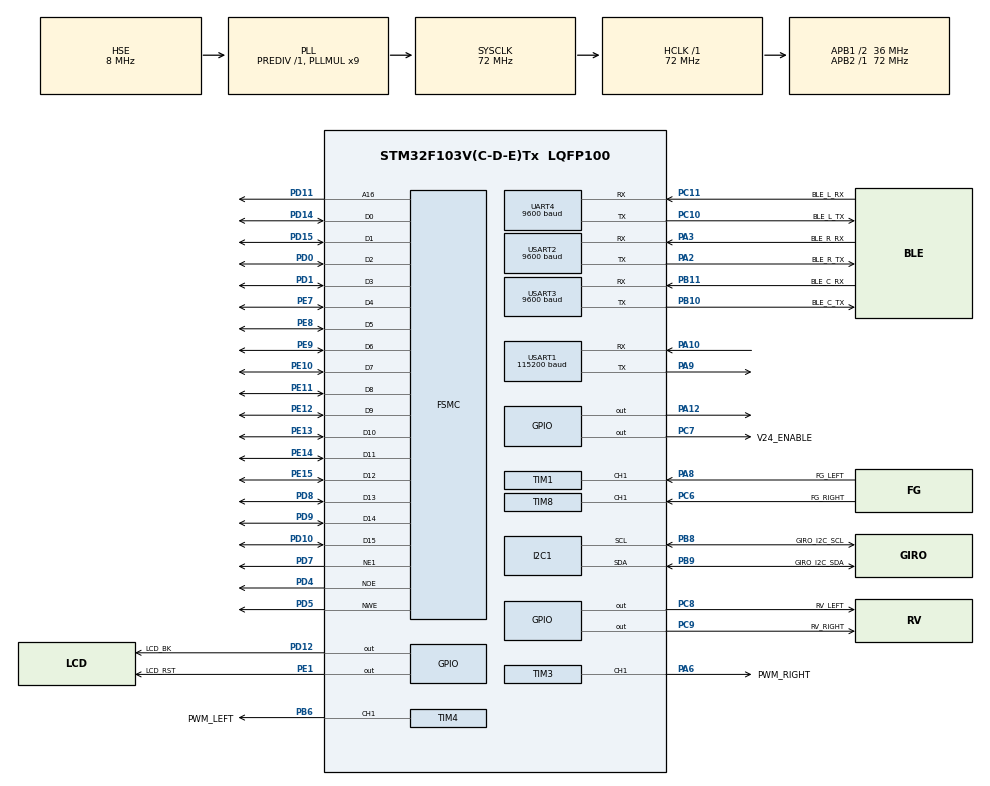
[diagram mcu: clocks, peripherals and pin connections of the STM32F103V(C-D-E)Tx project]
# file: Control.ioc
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Dma.Request0=UART4_RX
Dma.Request1=UART4_TX
Dma.Request2=USART2_RX
Dma.Request3=USART2_TX
Dma.Request4=USART1_RX
Dma.Request5=USART1_TX
Dma.Request6=USART3_RX
Dma.Request7=USART3_TX
Dma.UART4_RX.0.Direction=DMA_PERIPH_TO_MEMORY
Dma.UART4_RX.0.Instance=DMA2_Channel3
Dma.UART4_RX.0.MemDataAlignment=DMA_MDATAALIGN_BYTE
Dma.UART4_RX.0.MemInc=DMA_MINC_ENABLE
Dma.UART4_RX.0.Mode=DMA_CIRCULAR
Dma.UART4_RX.0.PeriphDataAlignment=DMA_PDATAALIGN_BYTE
Dma.UART4_RX.0.PeriphInc=DMA_PINC_DISABLE
Dma.UART4_RX.0.Priority=DMA_PRIORITY_HIGH
Dma.UART4_TX.1.Direction=DMA_MEMORY_TO_PERIPH
Dma.UART4_TX.1.Instance=DMA2_Channel5
Dma.UART4_TX.1.MemDataAlignment=DMA_MDATAALIGN_BYTE
Dma.UART4_TX.1.MemInc=DMA_MINC_ENABLE
Dma.UART4_TX.1.Mode=DMA_NORMAL
Dma.UART4_TX.1.PeriphDataAlignment=DMA_PDATAALIGN_BYTE
Dma.UART4_TX.1.PeriphInc=DMA_PINC_DISABLE
Dma.UART4_TX.1.Priority=DMA_PRIORITY_LOW
Dma.USART1_RX.4.Direction=DMA_PERIPH_TO_MEMORY
Dma.USART1_RX.4.Instance=DMA1_Channel5
Dma.USART1_RX.4.MemDataAlignment=DMA_MDATAALIGN_BYTE
Dma.USART1_RX.4.MemInc=DMA_MINC_ENABLE
Dma.USART1_RX.4.Mode=DMA_CIRCULAR
Dma.USART1_RX.4.PeriphDataAlignment=DMA_PDATAALIGN_BYTE
Dma.USART1_RX.4.PeriphInc=DMA_PINC_DISABLE
Dma.USART1_RX.4.Priority=DMA_PRIORITY_HIGH
Dma.USART1_TX.5.Direction=DMA_MEMORY_TO_PERIPH
Dma.USART1_TX.5.Instance=DMA1_Channel4
Dma.USART1_TX.5.MemDataAlignment=DMA_MDATAALIGN_BYTE
Dma.USART1_TX.5.MemInc=DMA_MINC_ENABLE
Dma.USART1_TX.5.Mode=DMA_NORMAL
Dma.USART1_TX.5.PeriphDataAlignment=DMA_PDATAALIGN_BYTE
Dma.USART1_TX.5.PeriphInc=DMA_PINC_DISABLE
Dma.USART1_TX.5.Priority=DMA_PRIORITY_LOW
Dma.USART2_RX.2.Direction=DMA_PERIPH_TO_MEMORY
Dma.USART2_RX.2.Instance=DMA1_Channel6
Dma.USART2_RX.2.MemDataAlignment=DMA_MDATAALIGN_BYTE
Dma.USART2_RX.2.MemInc=DMA_MINC_ENABLE
Dma.USART2_RX.2.Mode=DMA_CIRCULAR
Dma.USART2_RX.2.PeriphDataAlignment=DMA_PDATAALIGN_BYTE
Dma.USART2_RX.2.PeriphInc=DMA_PINC_DISABLE
Dma.USART2_RX.2.Priority=DMA_PRIORITY_HIGH
Dma.USART2_TX.3.Direction=DMA_MEMORY_TO_PERIPH
Dma.USART2_TX.3.Instance=DMA1_Channel7
Dma.USART2_TX.3.MemDataAlignment=DMA_MDATAALIGN_BYTE
Dma.USART2_TX.3.MemInc=DMA_MINC_ENABLE
Dma.USART2_TX.3.Mode=DMA_NORMAL
Dma.USART2_TX.3.PeriphDataAlignment=DMA_PDATAALIGN_BYTE
Dma.USART2_TX.3.PeriphInc=DMA_PINC_DISABLE
Dma.USART2_TX.3.Priority=DMA_PRIORITY_LOW
Dma.USART3_RX.6.Direction=DMA_PERIPH_TO_MEMORY
Dma.USART3_RX.6.Instance=DMA1_Channel3
Dma.USART3_RX.6.MemDataAlignment=DMA_MDATAALIGN_BYTE
Dma.USART3_RX.6.MemInc=DMA_MINC_ENABLE
Dma.USART3_RX.6.Mode=DMA_CIRCULAR
Dma.USART3_RX.6.PeriphDataAlignment=DMA_PDATAALIGN_BYTE
Dma.USART3_RX.6.PeriphInc=DMA_PINC_DISABLE
Dma.USART3_RX.6.Priority=DMA_PRIORITY_HIGH
Dma.USART3_TX.7.Direction=DMA_MEMORY_TO_PERIPH
Dma.USART3_TX.7.Instance=DMA1_Channel2
Dma.USART3_TX.7.MemDataAlignment=DMA_MDATAALIGN_BYTE
Dma.USART3_TX.7.MemInc=DMA_MINC_ENABLE
Dma.USART3_TX.7.Mode=DMA_NORMAL
Dma.USART3_TX.7.PeriphDataAlignment=DMA_PDATAALIGN_BYTE
Dma.USART3_TX.7.PeriphInc=DMA_PINC_DISABLE
Dma.USART3_TX.7.Priority=DMA_PRIORITY_LOW
FREERTOS.INCLUDE_uxTaskGetStackHighWaterMark=0
FREERTOS.Tasks01=RT_Main,24,512,rtmain,As weak,NULL,Static,RT_MainBuffer,RT_MainControlBlock
FREERTOS.configCHECK_FOR_STACK_OVERFLOW=0
FREERTOS.configENABLE_BACKWARD_COMPATIBILITY=0
FREERTOS.configTOTAL_HEAP_SIZE=32768
FREERTOS.configUSE_IDLE_HOOK=1
FREERTOS.configUSE_PREEMPTION=0
FREERTOS.configUSE_TRACE_FACILITY=0
Mcu.Family=STM32F1
Mcu.Name=STM32F103V(C-D-E)Tx
Mcu.Package=LQFP100
NVIC.DMA1_Channel2_IRQn=true\:5\:0\:false\:false\:true\:true\:false\:true
NVIC.DMA1_Channel3_IRQn=true\:5\:0\:false\:false\:true\:true\:false\:true
NVIC.DMA1_Channel4_IRQn=true\:5\:0\:false\:false\:true\:true\:false\:true
NVIC.DMA1_Channel5_IRQn=true\:5\:0\:false\:false\:true\:true\:false\:true
NVIC.DMA1_Channel6_IRQn=true\:5\:0\:false\:false\:true\:true\:false\:true
NVIC.DMA1_Channel7_IRQn=true\:5\:0\:false\:false\:true\:true\:false\:true
NVIC.DMA2_Channel3_IRQn=true\:5\:0\:false\:false\:true\:true\:false\:true
NVIC.DMA2_Channel4_5_IRQn=true\:5\:0\:false\:false\:true\:true\:false\:true
NVIC.PriorityGroup=NVIC_PRIORITYGROUP_4
NVIC.TIM1_CC_IRQn=true\:5\:0\:false\:false\:true\:false\:true\:true
NVIC.TIM7_IRQn=true\:0\:0\:false\:false\:true\:false\:false\:true
NVIC.TIM8_CC_IRQn=true\:5\:0\:false\:false\:true\:false\:true\:true
NVIC.TimeBase=TIM7_IRQn
NVIC.TimeBaseIP=TIM7
NVIC.UART4_IRQn=true\:5\:0\:false\:false\:true\:false\:true\:true
NVIC.USART1_IRQn=true\:5\:0\:false\:false\:true\:true\:true\:true
NVIC.USART2_IRQn=true\:5\:0\:false\:false\:true\:false\:true\:true
NVIC.USART3_IRQn=true\:5\:0\:false\:false\:true\:true\:true\:true
OSC_IN.Mode=HSE-External-Oscillator
OSC_IN.Signal=RCC_OSC_IN
OSC_OUT.Mode=HSE-External-Oscillator
OSC_OUT.Signal=RCC_OSC_OUT
PA10.Mode=Asynchronous
PA10.Signal=USART1_RX
PA12.PinState=GPIO_PIN_RESET
PA12.Signal=GPIO_Output
PA13.Mode=JTAG_4_pins
PA13.Signal=SYS_JTMS-SWDIO
PA14.Mode=JTAG_4_pins
PA14.Signal=SYS_JTCK-SWCLK
PA15.Mode=JTAG_4_pins
PA15.Signal=SYS_JTDI
PA2.GPIO_Label=BLE_R_TX
PA2.Mode=Asynchronous
PA2.Signal=USART2_TX
PA3.GPIO_Label=BLE_R_RX
PA3.Mode=Asynchronous
PA3.Signal=USART2_RX
PA6.GPIO_Label=PWM_RIGHT
PA6.GPIO_ModeDefaultPP=GPIO_MODE_AF_PP
PA6.GPIO_Speed=GPIO_SPEED_FREQ_HIGH
PA6.Signal=S_TIM3_CH1
PA8.GPIO_Label=FG_LEFT
PA8.GPIO_Mode=GPIO_MODE_INPUT
PA8.GPIO_PuPd=GPIO_NOPULL
PA8.Signal=S_TIM1_CH1
PA9.Mode=Asynchronous
PA9.Signal=USART1_TX
PB10.GPIO_Label=BLE_C_TX
PB10.Mode=Asynchronous
PB10.Signal=USART3_TX
PB11.GPIO_Label=BLE_C_RX
PB11.Mode=Asynchronous
PB11.Signal=USART3_RX
PB3.Mode=JTAG_4_pins
PB3.Signal=SYS_JTDO-TRACESWO
PB6.GPIO_Label=PWM_LEFT
PB6.GPIO_Speed=GPIO_SPEED_FREQ_HIGH
PB6.Signal=S_TIM4_CH1
PB8.GPIO_Label=GIRO_I2C_SCL
PB8.Mode=I2C
PB8.Signal=I2C1_SCL
PB9.GPIO_Label=GIRO_I2C_SDA
PB9.Mode=I2C
PB9.Signal=I2C1_SDA
PC10.GPIO_Label=BLE_L_TX
PC10.Mode=Asynchronous
PC10.Signal=UART4_TX
PC11.GPIO_Label=BLE_L_RX
PC11.Mode=Asynchronous
PC11.Signal=UART4_RX
PC14-OSC32_IN.Mode=LSE-External-Oscillator
PC14-OSC32_IN.Signal=RCC_OSC32_IN
PC15-OSC32_OUT.Mode=LSE-External-Oscillator
PC15-OSC32_OUT.Signal=RCC_OSC32_OUT
PC6.GPIO_Label=FG_RIGHT
PC6.GPIO_Mode=GPIO_MODE_INPUT
PC6.GPIO_PuPd=GPIO_NOPULL
PC6.Signal=S_TIM8_CH1
PC7.GPIO_Label=V24_ENABLE
PC7.Signal=GPIO_Output
PC8.GPIO_Label=RV_LEFT
PC8.Signal=GPIO_Output
PC9.GPIO_Label=RV_RIGHT
PC9.Signal=GPIO_Output
PD0.Mode=16b-d1
PD0.Signal=FSMC_D2
PD1.Mode=16b-d1
PD1.Signal=FSMC_D3
PD10.Mode=16b-d1
PD10.Signal=FSMC_D15
PD11.Mode=A16_1
PD11.Signal=FSMC_A16
PD12.GPIO_Label=LCD_BK
PD12.Signal=GPIO_Output
PD14.Mode=16b-d1
PD14.Signal=FSMC_D0
PD15.Mode=16b-d1
PD15.Signal=FSMC_D1
PD4.Mode=Lcd1
PD4.Signal=FSMC_NOE
PD5.Mode=Lcd1
PD5.Signal=FSMC_NWE
PD7.Mode=NorPsramChipSelect1_1
PD7.Signal=FSMC_NE1
PD8.Mode=16b-d1
PD8.Signal=FSMC_D13
PD9.Mode=16b-d1
PD9.Signal=FSMC_D14
PE1.GPIO_Label=LCD_RST
PE1.Signal=GPIO_Output
PE10.Mode=16b-d1
PE10.Signal=FSMC_D7
PE11.Mode=16b-d1
PE11.Signal=FSMC_D8
PE12.Mode=16b-d1
PE12.Signal=FSMC_D9
PE13.Mode=16b-d1
PE13.Signal=FSMC_D10
PE14.Mode=16b-d1
PE14.Signal=FSMC_D11
PE15.Mode=16b-d1
PE15.Signal=FSMC_D12
PE7.Mode=16b-d1
PE7.Signal=FSMC_D4
PE8.Mode=16b-d1
PE8.Signal=FSMC_D5
PE9.Mode=16b-d1
PE9.Signal=FSMC_D6
ProjectManager.HeapSize=0x200
ProjectManager.StackSize=0x400
ProjectManager.TargetToolchain=STM32CubeIDE
RCC.AHBFreq_Value=72000000
RCC.APB1CLKDivider=RCC_HCLK_DIV2
RCC.APB1Freq_Value=36000000
RCC.APB1TimFreq_Value=72000000
RCC.APB2Freq_Value=72000000
RCC.APB2TimFreq_Value=72000000
RCC.HCLKFreq_Value=72000000
RCC.PLLMUL=RCC_PLL_MUL9
RCC.PLLSourceVirtual=RCC_PLLSOURCE_HSE
RCC.SYSCLKFreq_VALUE=72000000
RCC.SYSCLKSource=RCC_SYSCLKSOURCE_PLLCLK
RCC.USBFreq_Value=72000000
SH.S_TIM1_CH1.0=TIM1_CH1,Input_Capture1_from_TI1
SH.S_TIM3_CH1.0=TIM3_CH1,PWM Generation1 CH1
SH.S_TIM4_CH1.0=TIM4_CH1,PWM Generation1 CH1
SH.S_TIM8_CH1.0=TIM8_CH1,Input_Capture1_from_TI1
TIM1.Channel-Input_Capture1_from_TI1=TIM_CHANNEL_1
TIM1.Prescaler=1023
TIM3.Channel-PWM\ Generation1\ CH1=TIM_CHANNEL_1
TIM3.Period=6999
TIM3.Pulse-PWM\ Generation1\ CH1=2099
TIM4.Channel-PWM\ Generation1\ CH1=TIM_CHANNEL_1
TIM4.Period=6999
TIM4.Pulse-PWM\ Generation1\ CH1=2099
TIM8.Channel-Input_Capture1_from_TI1=TIM_CHANNEL_1
TIM8.Prescaler=1023
UART4.BaudRate=9600
UART4.VirtualMode=Asynchronous
USART1.BaudRate=115200
USART1.VirtualMode=VM_ASYNC
USART2.BaudRate=9600
USART2.VirtualMode=VM_ASYNC
USART3.BaudRate=9600
USART3.VirtualMode=VM_ASYNC
VP_FREERTOS_VS_CMSIS_V2.Mode=CMSIS_V2
VP_SYS_VS_tim7.Mode=TIM7
VP_TIM1_VS_ClockSourceINT.Mode=Internal
VP_TIM3_VS_ClockSourceINT.Mode=Internal
VP_TIM4_VS_ClockSourceINT.Mode=Internal
VP_TIM8_VS_ClockSourceINT.Mode=Internal
board=custom

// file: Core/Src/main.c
/* USER CODE BEGIN Header */
/**
  ******************************************************************************
  * @file           : main.c
  * @brief          : Main program body
  ******************************************************************************
  * @attention
  *
  * <h2><center>&copy; Copyright (c) 2020 STMicroelectronics.
  * All rights reserved.</center></h2>
  *
  * This software component is licensed by ST under BSD 3-Clause license,
  * the "License"; You may not use this file except in compliance with the
  * License. You may obtain a copy of the License at:
  *                        opensource.org/licenses/BSD-3-Clause
  *
  ******************************************************************************
  */
/* USER CODE END Header */
#include "main.h"
#include "cmsis_os.h"

typedef StaticTask_t osStaticThreadDef_t;

I2C_HandleTypeDef hi2c1;

TIM_HandleTypeDef htim1;
TIM_HandleTypeDef htim3;
TIM_HandleTypeDef htim4;
TIM_HandleTypeDef htim8;

UART_HandleTypeDef huart4;
UART_HandleTypeDef huart1;
UART_HandleTypeDef huart2;
UART_HandleTypeDef huart3;
DMA_HandleTypeDef hdma_uart4_rx;
DMA_HandleTypeDef hdma_uart4_tx;
DMA_HandleTypeDef hdma_usart1_rx;
DMA_HandleTypeDef hdma_usart1_tx;
DMA_HandleTypeDef hdma_usart2_rx;
DMA_HandleTypeDef hdma_usart2_tx;
DMA_HandleTypeDef hdma_usart3_rx;
DMA_HandleTypeDef hdma_usart3_tx;

SRAM_HandleTypeDef hsram1;

/* Definitions for RT_Main */
osThreadId_t RT_MainHandle;
uint32_t RT_MainBuffer[ 512 ];
osStaticThreadDef_t RT_MainControlBlock;
const osThreadAttr_t RT_Main_attributes = {
  .name = "RT_Main",
  .stack_mem = &RT_MainBuffer[0],
  .stack_size = sizeof(RT_MainBuffer),
  .cb_mem = &RT_MainControlBlock,
  .cb_size = sizeof(RT_MainControlBlock),
  .priority = (osPriority_t) osPriorityNormal,
};

void SystemClock_Config(void);
static void MX_GPIO_Init(void);
static void MX_DMA_Init(void);
static void MX_FSMC_Init(void);
static void MX_TIM1_Init(void);
static void MX_TIM3_Init(void);
static void MX_TIM8_Init(void);
static void MX_TIM4_Init(void);
static void MX_UART4_Init(void);
static void MX_USART2_UART_Init(void);
static void MX_USART1_UART_Init(void);
static void MX_USART3_UART_Init(void);
static void MX_I2C1_Init(void);
void rtmain(void *argument);

int main(void)
{

  /* MCU Configuration--------------------------------------------------------*/

  /* Reset of all peripherals, Initializes the Flash interface and the Systick. */
  HAL_Init();

  /* Configure the system clock */
  SystemClock_Config();

  /* Initialize all configured peripherals */
  MX_GPIO_Init();
  MX_DMA_Init();
  MX_FSMC_Init();
  MX_TIM1_Init();
  MX_TIM3_Init();
  MX_TIM8_Init();
  MX_TIM4_Init();
  MX_UART4_Init();
  MX_USART2_UART_Init();
  MX_USART1_UART_Init();
  MX_USART3_UART_Init();
  MX_I2C1_Init();

  /* Init scheduler */
  osKernelInitialize();

  /* Create the thread(s) */
  /* creation of RT_Main */
  RT_MainHandle = osThreadNew(rtmain, NULL, &RT_Main_attributes);

  /* Start scheduler */
  osKernelStart();

  /* We should never get here as control is now taken by the scheduler */
  /* Infinite loop */
    while (1) {

    }
}

void SystemClock_Config(void)
{
  RCC_OscInitTypeDef RCC_OscInitStruct = {0};
  RCC_ClkInitTypeDef RCC_ClkInitStruct = {0};

  /** Initializes the RCC Oscillators according to the specified parameters
  * in the RCC_OscInitTypeDef structure.
  */
  RCC_OscInitStruct.OscillatorType = RCC_OSCILLATORTYPE_HSE;
  RCC_OscInitStruct.HSEState = RCC_HSE_ON;
  RCC_OscInitStruct.HSEPredivValue = RCC_HSE_PREDIV_DIV1;
  RCC_OscInitStruct.HSIState = RCC_HSI_ON;
  RCC_OscInitStruct.PLL.PLLState = RCC_PLL_ON;
  RCC_OscInitStruct.PLL.PLLSource = RCC_PLLSOURCE_HSE;
  RCC_OscInitStruct.PLL.PLLMUL = RCC_PLL_MUL9;
  if (HAL_RCC_OscConfig(&RCC_OscInitStruct) != HAL_OK)
  {
    Error_Handler();
  }
  /** Initializes the CPU, AHB and APB buses clocks
  */
  RCC_ClkInitStruct.ClockType = RCC_CLOCKTYPE_HCLK|RCC_CLOCKTYPE_SYSCLK
                              |RCC_CLOCKTYPE_PCLK1|RCC_CLOCKTYPE_PCLK2;
  RCC_ClkInitStruct.SYSCLKSource = RCC_SYSCLKSOURCE_PLLCLK;
  RCC_ClkInitStruct.AHBCLKDivider = RCC_SYSCLK_DIV1;
  RCC_ClkInitStruct.APB1CLKDivider = RCC_HCLK_DIV2;
  RCC_ClkInitStruct.APB2CLKDivider = RCC_HCLK_DIV1;

  if (HAL_RCC_ClockConfig(&RCC_ClkInitStruct, FLASH_LATENCY_2) != HAL_OK)
  {
    Error_Handler();
  }
}

static void MX_I2C1_Init(void)
{

  hi2c1.Instance = I2C1;
  hi2c1.Init.ClockSpeed = 100000;
  hi2c1.Init.DutyCycle = I2C_DUTYCYCLE_2;
  hi2c1.Init.OwnAddress1 = 0;
  hi2c1.Init.AddressingMode = I2C_ADDRESSINGMODE_7BIT;
  hi2c1.Init.DualAddressMode = I2C_DUALADDRESS_DISABLE;
  hi2c1.Init.OwnAddress2 = 0;
  hi2c1.Init.GeneralCallMode = I2C_GENERALCALL_DISABLE;
  hi2c1.Init.NoStretchMode = I2C_NOSTRETCH_DISABLE;
  if (HAL_I2C_Init(&hi2c1) != HAL_OK)
  {
    Error_Handler();
  }

}

static void MX_TIM1_Init(void)
{

  TIM_ClockConfigTypeDef sClockSourceConfig = {0};
  TIM_MasterConfigTypeDef sMasterConfig = {0};
  TIM_IC_InitTypeDef sConfigIC = {0};

  htim1.Instance = TIM1;
  htim1.Init.Prescaler = 1023;
  htim1.Init.CounterMode = TIM_COUNTERMODE_UP;
  htim1.Init.Period = 65535;
  htim1.Init.ClockDivision = TIM_CLOCKDIVISION_DIV1;
  htim1.Init.RepetitionCounter = 0;
  htim1.Init.AutoReloadPreload = TIM_AUTORELOAD_PRELOAD_DISABLE;
  if (HAL_TIM_Base_Init(&htim1) != HAL_OK)
  {
    Error_Handler();
  }
  sClockSourceConfig.ClockSource = TIM_CLOCKSOURCE_INTERNAL;
  if (HAL_TIM_ConfigClockSource(&htim1, &sClockSourceConfig) != HAL_OK)
  {
    Error_Handler();
  }
  if (HAL_TIM_IC_Init(&htim1) != HAL_OK)
  {
    Error_Handler();
  }
  sMasterConfig.MasterOutputTrigger = TIM_TRGO_RESET;
  sMasterConfig.MasterSlaveMode = TIM_MASTERSLAVEMODE_DISABLE;
  if (HAL_TIMEx_MasterConfigSynchronization(&htim1, &sMasterConfig) != HAL_OK)
  {
    Error_Handler();
  }
  sConfigIC.ICPolarity = TIM_INPUTCHANNELPOLARITY_RISING;
  sConfigIC.ICSelection = TIM_ICSELECTION_DIRECTTI;
  sConfigIC.ICPrescaler = TIM_ICPSC_DIV1;
  sConfigIC.ICFilter = 0;
  if (HAL_TIM_IC_ConfigChannel(&htim1, &sConfigIC, TIM_CHANNEL_1) != HAL_OK)
  {
    Error_Handler();
  }

}

static void MX_TIM3_Init(void)
{

  TIM_ClockConfigTypeDef sClockSourceConfig = {0};
  TIM_MasterConfigTypeDef sMasterConfig = {0};
  TIM_OC_InitTypeDef sConfigOC = {0};

  htim3.Instance = TIM3;
  htim3.Init.Prescaler = 0;
  htim3.Init.CounterMode = TIM_COUNTERMODE_UP;
  htim3.Init.Period = 6999;
  htim3.Init.ClockDivision = TIM_CLOCKDIVISION_DIV1;
  htim3.Init.AutoReloadPreload = TIM_AUTORELOAD_PRELOAD_DISABLE;
  if (HAL_TIM_Base_Init(&htim3) != HAL_OK)
  {
    Error_Handler();
  }
  sClockSourceConfig.ClockSource = TIM_CLOCKSOURCE_INTERNAL;
  if (HAL_TIM_ConfigClockSource(&htim3, &sClockSourceConfig) != HAL_OK)
  {
    Error_Handler();
  }
  if (HAL_TIM_PWM_Init(&htim3) != HAL_OK)
  {
    Error_Handler();
  }
  sMasterConfig.MasterOutputTrigger = TIM_TRGO_RESET;
  sMasterConfig.MasterSlaveMode = TIM_MASTERSLAVEMODE_DISABLE;
  if (HAL_TIMEx_MasterConfigSynchronization(&htim3, &sMasterConfig) != HAL_OK)
  {
    Error_Handler();
  }
  sConfigOC.OCMode = TIM_OCMODE_PWM1;
  sConfigOC.Pulse = 2099;
  sConfigOC.OCPolarity = TIM_OCPOLARITY_HIGH;
  sConfigOC.OCFastMode = TIM_OCFAST_DISABLE;
  if (HAL_TIM_PWM_ConfigChannel(&htim3, &sConfigOC, TIM_CHANNEL_1) != HAL_OK)
  {
    Error_Handler();
  }
  HAL_TIM_MspPostInit(&htim3);

}

static void MX_TIM4_Init(void)
{

  TIM_ClockConfigTypeDef sClockSourceConfig = {0};
  TIM_MasterConfigTypeDef sMasterConfig = {0};
  TIM_OC_InitTypeDef sConfigOC = {0};

  htim4.Instance = TIM4;
  htim4.Init.Prescaler = 0;
  htim4.Init.CounterMode = TIM_COUNTERMODE_UP;
  htim4.Init.Period = 6999;
  htim4.Init.ClockDivision = TIM_CLOCKDIVISION_DIV1;
  htim4.Init.AutoReloadPreload = TIM_AUTORELOAD_PRELOAD_DISABLE;
  if (HAL_TIM_Base_Init(&htim4) != HAL_OK)
  {
    Error_Handler();
  }
  sClockSourceConfig.ClockSource = TIM_CLOCKSOURCE_INTERNAL;
  if (HAL_TIM_ConfigClockSource(&htim4, &sClockSourceConfig) != HAL_OK)
  {
    Error_Handler();
  }
  if (HAL_TIM_PWM_Init(&htim4) != HAL_OK)
  {
    Error_Handler();
  }
  sMasterConfig.MasterOutputTrigger = TIM_TRGO_RESET;
  sMasterConfig.MasterSlaveMode = TIM_MASTERSLAVEMODE_DISABLE;
  if (HAL_TIMEx_MasterConfigSynchronization(&htim4, &sMasterConfig) != HAL_OK)
  {
    Error_Handler();
  }
  sConfigOC.OCMode = TIM_OCMODE_PWM1;
  sConfigOC.Pulse = 2099;
  sConfigOC.OCPolarity = TIM_OCPOLARITY_HIGH;
  sConfigOC.OCFastMode = TIM_OCFAST_DISABLE;
  if (HAL_TIM_PWM_ConfigChannel(&htim4, &sConfigOC, TIM_CHANNEL_1) != HAL_OK)
  {
    Error_Handler();
  }
  HAL_TIM_MspPostInit(&htim4);

}

static void MX_TIM8_Init(void)
{

  TIM_ClockConfigTypeDef sClockSourceConfig = {0};
  TIM_MasterConfigTypeDef sMasterConfig = {0};
  TIM_IC_InitTypeDef sConfigIC = {0};

  htim8.Instance = TIM8;
  htim8.Init.Prescaler = 1023;
  htim8.Init.CounterMode = TIM_COUNTERMODE_UP;
  htim8.Init.Period = 65535;
  htim8.Init.ClockDivision = TIM_CLOCKDIVISION_DIV1;
  htim8.Init.RepetitionCounter = 0;
  htim8.Init.AutoReloadPreload = TIM_AUTORELOAD_PRELOAD_DISABLE;
  if (HAL_TIM_Base_Init(&htim8) != HAL_OK)
  {
    Error_Handler();
  }
  sClockSourceConfig.ClockSource = TIM_CLOCKSOURCE_INTERNAL;
  if (HAL_TIM_ConfigClockSource(&htim8, &sClockSourceConfig) != HAL_OK)
  {
    Error_Handler();
  }
  if (HAL_TIM_IC_Init(&htim8) != HAL_OK)
  {
    Error_Handler();
  }
  sMasterConfig.MasterOutputTrigger = TIM_TRGO_RESET;
  sMasterConfig.MasterSlaveMode = TIM_MASTERSLAVEMODE_DISABLE;
  if (HAL_TIMEx_MasterConfigSynchronization(&htim8, &sMasterConfig) != HAL_OK)
  {
    Error_Handler();
  }
  sConfigIC.ICPolarity = TIM_INPUTCHANNELPOLARITY_RISING;
  sConfigIC.ICSelection = TIM_ICSELECTION_DIRECTTI;
  sConfigIC.ICPrescaler = TIM_ICPSC_DIV1;
  sConfigIC.ICFilter = 0;
  if (HAL_TIM_IC_ConfigChannel(&htim8, &sConfigIC, TIM_CHANNEL_1) != HAL_OK)
  {
    Error_Handler();
  }

}

static void MX_UART4_Init(void)
{

  huart4.Instance = UART4;
  huart4.Init.BaudRate = 9600;
  huart4.Init.WordLength = UART_WORDLENGTH_8B;
  huart4.Init.StopBits = UART_STOPBITS_1;
  huart4.Init.Parity = UART_PARITY_NONE;
  huart4.Init.Mode = UART_MODE_TX_RX;
  huart4.Init.HwFlowCtl = UART_HWCONTROL_NONE;
  huart4.Init.OverSampling = UART_OVERSAMPLING_16;
  if (HAL_UART_Init(&huart4) != HAL_OK)
  {
    Error_Handler();
  }
  /* USER CODE BEGIN UART4_Init 2 */
  __HAL_UART_ENABLE_IT(&huart4, UART_IT_IDLE);

  /* USER CODE END UART4_Init 2 */

}

static void MX_USART1_UART_Init(void)
{

  huart1.Instance = USART1;
  huart1.Init.BaudRate = 115200;
  huart1.Init.WordLength = UART_WORDLENGTH_8B;
  huart1.Init.StopBits = UART_STOPBITS_1;
  huart1.Init.Parity = UART_PARITY_NONE;
  huart1.Init.Mode = UART_MODE_TX_RX;
  huart1.Init.HwFlowCtl = UART_HWCONTROL_NONE;
  huart1.Init.OverSampling = UART_OVERSAMPLING_16;
  if (HAL_UART_Init(&huart1) != HAL_OK)
  {
    Error_Handler();
  }
  /* USER CODE BEGIN USART1_Init 2 */
  __HAL_UART_ENABLE_IT(&huart1, UART_IT_IDLE);
  /* USER CODE END USART1_Init 2 */

}

static void MX_USART2_UART_Init(void)
{

  huart2.Instance = USART2;
  huart2.Init.BaudRate = 9600;
  huart2.Init.WordLength = UART_WORDLENGTH_8B;
  huart2.Init.StopBits = UART_STOPBITS_1;
  huart2.Init.Parity = UART_PARITY_NONE;
  huart2.Init.Mode = UART_MODE_TX_RX;
  huart2.Init.HwFlowCtl = UART_HWCONTROL_NONE;
  huart2.Init.OverSampling = UART_OVERSAMPLING_16;
  if (HAL_UART_Init(&huart2) != HAL_OK)
  {
    Error_Handler();
  }
  /* USER CODE BEGIN USART2_Init 2 */
  __HAL_UART_ENABLE_IT(&huart2, UART_IT_IDLE);
  /* USER CODE END USART2_Init 2 */

}

static void MX_USART3_UART_Init(void)
{

  huart3.Instance = USART3;
  huart3.Init.BaudRate = 9600;
  huart3.Init.WordLength = UART_WORDLENGTH_8B;
  huart3.Init.StopBits = UART_STOPBITS_1;
  huart3.Init.Parity = UART_PARITY_NONE;
  huart3.Init.Mode = UART_MODE_TX_RX;
  huart3.Init.HwFlowCtl = UART_HWCONTROL_NONE;
  huart3.Init.OverSampling = UART_OVERSAMPLING_16;
  if (HAL_UART_Init(&huart3) != HAL_OK)
  {
    Error_Handler();
  }
  /* USER CODE BEGIN USART3_Init 2 */
  __HAL_UART_ENABLE_IT(&huart3, UART_IT_IDLE);

  /* USER CODE END USART3_Init 2 */

}

static void MX_DMA_Init(void)
{

  /* DMA controller clock enable */
  __HAL_RCC_DMA2_CLK_ENABLE();
  __HAL_RCC_DMA1_CLK_ENABLE();

  /* DMA interrupt init */
  /* DMA1_Channel2_IRQn interrupt configuration */
  HAL_NVIC_SetPriority(DMA1_Channel2_IRQn, 5, 0);
  HAL_NVIC_EnableIRQ(DMA1_Channel2_IRQn);
  /* DMA1_Channel3_IRQn interrupt configuration */
  HAL_NVIC_SetPriority(DMA1_Channel3_IRQn, 5, 0);
  HAL_NVIC_EnableIRQ(DMA1_Channel3_IRQn);
  /* DMA1_Channel4_IRQn interrupt configuration */
  HAL_NVIC_SetPriority(DMA1_Channel4_IRQn, 5, 0);
  HAL_NVIC_EnableIRQ(DMA1_Channel4_IRQn);
  /* DMA1_Channel5_IRQn interrupt configuration */
  HAL_NVIC_SetPriority(DMA1_Channel5_IRQn, 5, 0);
  HAL_NVIC_EnableIRQ(DMA1_Channel5_IRQn);
  /* DMA1_Channel6_IRQn interrupt configuration */
  HAL_NVIC_SetPriority(DMA1_Channel6_IRQn, 5, 0);
  HAL_NVIC_EnableIRQ(DMA1_Channel6_IRQn);
  /* DMA1_Channel7_IRQn interrupt configuration */
  HAL_NVIC_SetPriority(DMA1_Channel7_IRQn, 5, 0);
  HAL_NVIC_EnableIRQ(DMA1_Channel7_IRQn);
  /* DMA2_Channel3_IRQn interrupt configuration */
  HAL_NVIC_SetPriority(DMA2_Channel3_IRQn, 5, 0);
  HAL_NVIC_EnableIRQ(DMA2_Channel3_IRQn);
  /* DMA2_Channel4_5_IRQn interrupt configuration */
  HAL_NVIC_SetPriority(DMA2_Channel4_5_IRQn, 5, 0);
  HAL_NVIC_EnableIRQ(DMA2_Channel4_5_IRQn);

}

static void MX_GPIO_Init(void)
{
  GPIO_InitTypeDef GPIO_InitStruct = {0};

  /* GPIO Ports Clock Enable */
  __HAL_RCC_GPIOE_CLK_ENABLE();
  __HAL_RCC_GPIOC_CLK_ENABLE();
  __HAL_RCC_GPIOA_CLK_ENABLE();
  __HAL_RCC_GPIOB_CLK_ENABLE();
  __HAL_RCC_GPIOD_CLK_ENABLE();

  /*Configure GPIO pin Output Level */
  HAL_GPIO_WritePin(LCD_BK_GPIO_Port, LCD_BK_Pin, GPIO_PIN_RESET);

  /*Configure GPIO pin Output Level */
  HAL_GPIO_WritePin(GPIOC, V24_ENABLE_Pin|RV_LEFT_Pin|RV_RIGHT_Pin, GPIO_PIN_RESET);

  /*Configure GPIO pin Output Level */
  HAL_GPIO_WritePin(GPIOA, GPIO_PIN_12, GPIO_PIN_RESET);

  /*Configure GPIO pin Output Level */
  HAL_GPIO_WritePin(LCD_RST_GPIO_Port, LCD_RST_Pin, GPIO_PIN_RESET);

  /*Configure GPIO pins : PE2 PE3 PE4 PE5
                           PE6 PE0 */
  GPIO_InitStruct.Pin = GPIO_PIN_2|GPIO_PIN_3|GPIO_PIN_4|GPIO_PIN_5
                          |GPIO_PIN_6|GPIO_PIN_0;
  GPIO_InitStruct.Mode = GPIO_MODE_ANALOG;
  HAL_GPIO_Init(GPIOE, &GPIO_InitStruct);

  /*Configure GPIO pins : PC13 PC0 PC1 PC2
                           PC3 PC4 PC5 PC12 */
  GPIO_InitStruct.Pin = GPIO_PIN_13|GPIO_PIN_0|GPIO_PIN_1|GPIO_PIN_2
                          |GPIO_PIN_3|GPIO_PIN_4|GPIO_PIN_5|GPIO_PIN_12;
  GPIO_InitStruct.Mode = GPIO_MODE_ANALOG;
  HAL_GPIO_Init(GPIOC, &GPIO_InitStruct);

  /*Configure GPIO pins : PA0 PA1 PA4 PA5
                           PA7 PA11 */
  GPIO_InitStruct.Pin = GPIO_PIN_0|GPIO_PIN_1|GPIO_PIN_4|GPIO_PIN_5
                          |GPIO_PIN_7|GPIO_PIN_11;
  GPIO_InitStruct.Mode = GPIO_MODE_ANALOG;
  HAL_GPIO_Init(GPIOA, &GPIO_InitStruct);

  /*Configure GPIO pins : PB0 PB1 PB2 PB12
                           PB13 PB14 PB15 PB4
                           PB5 PB7 */
  GPIO_InitStruct.Pin = GPIO_PIN_0|GPIO_PIN_1|GPIO_PIN_2|GPIO_PIN_12
                          |GPIO_PIN_13|GPIO_PIN_14|GPIO_PIN_15|GPIO_PIN_4
                          |GPIO_PIN_5|GPIO_PIN_7;
  GPIO_InitStruct.Mode = GPIO_MODE_ANALOG;
  HAL_GPIO_Init(GPIOB, &GPIO_InitStruct);

  /*Configure GPIO pin : LCD_BK_Pin */
  GPIO_InitStruct.Pin = LCD_BK_Pin;
  GPIO_InitStruct.Mode = GPIO_MODE_OUTPUT_PP;
  GPIO_InitStruct.Pull = GPIO_NOPULL;
  GPIO_InitStruct.Speed = GPIO_SPEED_FREQ_LOW;
  HAL_GPIO_Init(LCD_BK_GPIO_Port, &GPIO_InitStruct);

  /*Configure GPIO pins : PD13 PD2 PD3 PD6 */
  GPIO_InitStruct.Pin = GPIO_PIN_13|GPIO_PIN_2|GPIO_PIN_3|GPIO_PIN_6;
  GPIO_InitStruct.Mode = GPIO_MODE_ANALOG;
  HAL_GPIO_Init(GPIOD, &GPIO_InitStruct);

  /*Configure GPIO pins : V24_ENABLE_Pin RV_LEFT_Pin RV_RIGHT_Pin */
  GPIO_InitStruct.Pin = V24_ENABLE_Pin|RV_LEFT_Pin|RV_RIGHT_Pin;
  GPIO_InitStruct.Mode = GPIO_MODE_OUTPUT_PP;
  GPIO_InitStruct.Pull = GPIO_NOPULL;
  GPIO_InitStruct.Speed = GPIO_SPEED_FREQ_LOW;
  HAL_GPIO_Init(GPIOC, &GPIO_InitStruct);

  /*Configure GPIO pin : PA12 */
  GPIO_InitStruct.Pin = GPIO_PIN_12;
  GPIO_InitStruct.Mode = GPIO_MODE_OUTPUT_PP;
  GPIO_InitStruct.Pull = GPIO_NOPULL;
  GPIO_InitStruct.Speed = GPIO_SPEED_FREQ_LOW;
  HAL_GPIO_Init(GPIOA, &GPIO_InitStruct);

  /*Configure GPIO pin : LCD_RST_Pin */
  GPIO_InitStruct.Pin = LCD_RST_Pin;
  GPIO_InitStruct.Mode = GPIO_MODE_OUTPUT_PP;
  GPIO_InitStruct.Pull = GPIO_NOPULL;
  GPIO_InitStruct.Speed = GPIO_SPEED_FREQ_LOW;
  HAL_GPIO_Init(LCD_RST_GPIO_Port, &GPIO_InitStruct);

}

/* FSMC initialization function */
static void MX_FSMC_Init(void)
{

  FSMC_NORSRAM_TimingTypeDef Timing = {0};

  /** Perform the SRAM1 memory initialization sequence
  */
  hsram1.Instance = FSMC_NORSRAM_DEVICE;
  hsram1.Extended = FSMC_NORSRAM_EXTENDED_DEVICE;
  /* hsram1.Init */
  hsram1.Init.NSBank = FSMC_NORSRAM_BANK1;
  hsram1.Init.DataAddressMux = FSMC_DATA_ADDRESS_MUX_DISABLE;
  hsram1.Init.MemoryType = FSMC_MEMORY_TYPE_SRAM;
  hsram1.Init.MemoryDataWidth = FSMC_NORSRAM_MEM_BUS_WIDTH_16;
  hsram1.Init.BurstAccessMode = FSMC_BURST_ACCESS_MODE_DISABLE;
  hsram1.Init.WaitSignalPolarity = FSMC_WAIT_SIGNAL_POLARITY_LOW;
  hsram1.Init.WrapMode = FSMC_WRAP_MODE_DISABLE;
  hsram1.Init.WaitSignalActive = FSMC_WAIT_TIMING_BEFORE_WS;
  hsram1.Init.WriteOperation = FSMC_WRITE_OPERATION_ENABLE;
  hsram1.Init.WaitSignal = FSMC_WAIT_SIGNAL_DISABLE;
  hsram1.Init.ExtendedMode = FSMC_EXTENDED_MODE_DISABLE;
  hsram1.Init.AsynchronousWait = FSMC_ASYNCHRONOUS_WAIT_DISABLE;
  hsram1.Init.WriteBurst = FSMC_WRITE_BURST_DISABLE;
  /* Timing */
  Timing.AddressSetupTime = 15;
  Timing.AddressHoldTime = 15;
  Timing.DataSetupTime = 255;
  Timing.BusTurnAroundDuration = 15;
  Timing.CLKDivision = 16;
  Timing.DataLatency = 17;
  Timing.AccessMode = FSMC_ACCESS_MODE_A;
  /* ExtTiming */

  if (HAL_SRAM_Init(&hsram1, &Timing, NULL) != HAL_OK)
  {
    Error_Handler( );
  }

  /** Disconnect NADV
  */

  __HAL_AFIO_FSMCNADV_DISCONNECTED();

}

__weak void rtmain(void *argument)
{
  for(;;)
  {
    osDelay(1);
  }
}

 /**
  * @brief  Period elapsed callback in non blocking mode
  * @note   This function is called  when TIM7 interrupt took place, inside
  * HAL_TIM_IRQHandler(). It makes a direct call to HAL_IncTick() to increment
  * a global variable "uwTick" used as application time base.
  * @param  htim : TIM handle
  * @retval None
  */
void HAL_TIM_PeriodElapsedCallback(TIM_HandleTypeDef *htim)
{
  if (htim->Instance == TIM7) {
    HAL_IncTick();
  }
}

void Error_Handler(void)
{
}

/************************ (C) COPYRIGHT STMicroelectronics *****END OF FILE****/
